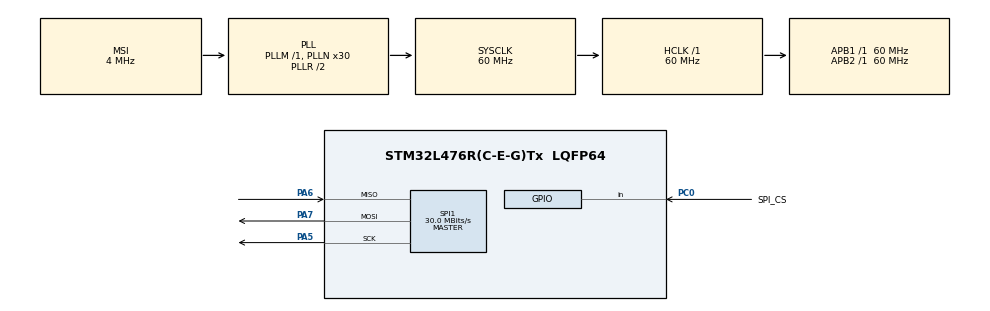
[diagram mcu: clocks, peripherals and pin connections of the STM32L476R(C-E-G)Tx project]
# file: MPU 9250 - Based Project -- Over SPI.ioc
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Mcu.Family=STM32L4
Mcu.Name=STM32L476R(C-E-G)Tx
Mcu.Package=LQFP64
NVIC.PriorityGroup=NVIC_PRIORITYGROUP_4
PA5.Mode=Full_Duplex_Master
PA5.Signal=SPI1_SCK
PA6.Mode=Full_Duplex_Master
PA6.Signal=SPI1_MISO
PA7.Mode=Full_Duplex_Master
PA7.Signal=SPI1_MOSI
PC0.GPIO_Label=SPI_CS
PC0.Signal=GPIO_Input
ProjectManager.HeapSize=0x200
ProjectManager.StackSize=0x400
ProjectManager.TargetToolchain=STM32CubeIDE
RCC.AHBFreq_Value=60000000
RCC.APB1Freq_Value=60000000
RCC.APB1TimFreq_Value=60000000
RCC.APB2Freq_Value=60000000
RCC.APB2TimFreq_Value=60000000
RCC.CortexFreq_Value=60000000
RCC.HCLKFreq_Value=60000000
RCC.HSE_VALUE=8000000
RCC.HSI_VALUE=16000000
RCC.LSE_VALUE=32768
RCC.MSI_VALUE=4000000
RCC.PLLN=30
RCC.SYSCLKFreq_VALUE=60000000
RCC.SYSCLKSource=RCC_SYSCLKSOURCE_PLLCLK
RCC.VCOOutputFreq_Value=120000000
SPI1.CalculateBaudRate=30.0 MBits/s
SPI1.DataSize=SPI_DATASIZE_8BIT
SPI1.Direction=SPI_DIRECTION_2LINES
SPI1.Mode=SPI_MODE_MASTER
SPI1.VirtualType=VM_MASTER
board=custom

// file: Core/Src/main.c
/* USER CODE BEGIN Header */
/**
  ******************************************************************************
  * @file           : main.c
  * @brief          : Main program body
  ******************************************************************************
  * @attention
  *
  * Copyright (c) 2023 STMicroelectronics.
  * All rights reserved.
  *
  * This software is licensed under terms that can be found in the LICENSE file
  * in the root directory of this software component.
  * If no LICENSE file comes with this software, it is provided AS-IS.
  *
  ******************************************************************************
  */
/* USER CODE END Header */
#include "main.h"
#include "spi.h"
#include "gpio.h"

/* USER CODE BEGIN Includes */
#include "MPU9250.h"

/* USER CODE END Includes */

void SystemClock_Config(void);

/* USER CODE BEGIN 0 */

int16_t AccData[3], GyroData[3], MagData[3];

/* USER CODE END 0 */

int main(void)
{

  /* MCU Configuration--------------------------------------------------------*/

  /* Reset of all peripherals, Initializes the Flash interface and the Systick. */
  HAL_Init();

  /* Configure the system clock */
  SystemClock_Config();

  /* Initialize all configured peripherals */
  MX_GPIO_Init();
  MX_SPI1_Init();
  /* USER CODE BEGIN 2 */

  MPU9250_Init();

  /* USER CODE END 2 */

  /* Infinite loop */
  while (1)
  {

    /* USER CODE BEGIN 3 */

	MPU9250_GetData(AccData,GyroData,MagData);

	/*
	printf("%08d;%08d;%08d;%08d;%08d;%08d;%08d;%08d;%08d\n",
	  (int16_t)AccData[0], (int16_t)AccData[1], (int16_t)AccData[2],
	  (int16_t)GyroData[0], (int16_t)GyroData[1], (int16_t)GyroData[2],
	  (int16_t)MagData[0], (int16_t)MagData[1], (int16_t)MagData[2]);
	*/
  }
  /* USER CODE END 3 */
}

void SystemClock_Config(void)
{
  RCC_OscInitTypeDef RCC_OscInitStruct = {0};
  RCC_ClkInitTypeDef RCC_ClkInitStruct = {0};

  /** Configure the main internal regulator output voltage
  */
  if (HAL_PWREx_ControlVoltageScaling(PWR_REGULATOR_VOLTAGE_SCALE1) != HAL_OK)
  {
    Error_Handler();
  }

  /** Initializes the RCC Oscillators according to the specified parameters
  * in the RCC_OscInitTypeDef structure.
  */
  RCC_OscInitStruct.OscillatorType = RCC_OSCILLATORTYPE_MSI;
  RCC_OscInitStruct.MSIState = RCC_MSI_ON;
  RCC_OscInitStruct.MSICalibrationValue = 0;
  RCC_OscInitStruct.MSIClockRange = RCC_MSIRANGE_6;
  RCC_OscInitStruct.PLL.PLLState = RCC_PLL_ON;
  RCC_OscInitStruct.PLL.PLLSource = RCC_PLLSOURCE_MSI;
  RCC_OscInitStruct.PLL.PLLM = 1;
  RCC_OscInitStruct.PLL.PLLN = 30;
  RCC_OscInitStruct.PLL.PLLP = RCC_PLLP_DIV7;
  RCC_OscInitStruct.PLL.PLLQ = RCC_PLLQ_DIV2;
  RCC_OscInitStruct.PLL.PLLR = RCC_PLLR_DIV2;
  if (HAL_RCC_OscConfig(&RCC_OscInitStruct) != HAL_OK)
  {
    Error_Handler();
  }

  /** Initializes the CPU, AHB and APB buses clocks
  */
  RCC_ClkInitStruct.ClockType = RCC_CLOCKTYPE_HCLK|RCC_CLOCKTYPE_SYSCLK
                              |RCC_CLOCKTYPE_PCLK1|RCC_CLOCKTYPE_PCLK2;
  RCC_ClkInitStruct.SYSCLKSource = RCC_SYSCLKSOURCE_PLLCLK;
  RCC_ClkInitStruct.AHBCLKDivider = RCC_SYSCLK_DIV1;
  RCC_ClkInitStruct.APB1CLKDivider = RCC_HCLK_DIV1;
  RCC_ClkInitStruct.APB2CLKDivider = RCC_HCLK_DIV1;

  if (HAL_RCC_ClockConfig(&RCC_ClkInitStruct, FLASH_LATENCY_3) != HAL_OK)
  {
    Error_Handler();
  }
}

void Error_Handler(void)
{
  __disable_irq();
  while (1)
  {
  }
}
